# STM32F745 register map
File version: 1.6
CPU: CM7 r0p1, little endian, MPU, FPU, 4 interrupt priority bits
Registers are 32-bit, read-write, reset 0x0 unless marked. A register's access mark holds for its fields unless they carry their own. Offsets are from the block's base; [hi:lo] are bit positions.

## Ethernet_MMC — Ethernet: MAC management counters
Base 0x40028100
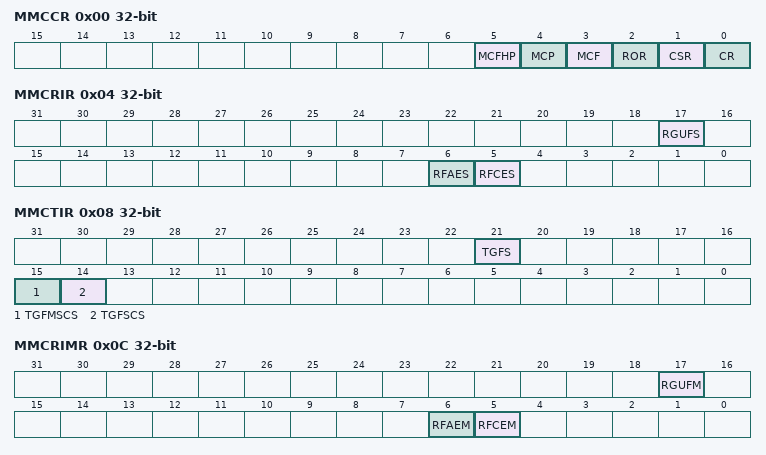
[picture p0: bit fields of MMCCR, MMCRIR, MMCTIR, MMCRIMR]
0x00 MMCCR — Ethernet MMC control register
  [5] MCFHP — MMC counter Full-Half preset
    0=AlmostHalf (When MCP is set, MMC counters are preset to almost-half value 0x7FFF_FFF0); 1=AlmostFull (When MCP is set, MMC counters are preset to almost-full value 0xFFFF_FFF0)
  [4] MCP — MMC counter preset
    1=Preset (MMC counters will be preset to almost full or almost half. Cleared automatically)
  [3] MCF — MMC counter freeze
    0=Unfrozen (All MMC counters update normally); 1=Frozen (All MMC counters frozen to their current value)
  [2] ROR — Reset on read
    0=Disabled (MMC counters do not reset on read); 1=Enabled (MMC counters reset to zero after read)
  [1] CSR — Counter stop rollover
    0=Disabled (Counters roll over to zero after reaching the maximum value); 1=Enabled (Counters do not roll over to zero after reaching the maximum value)
  [0] CR — Counter reset
    1=Reset all counters. Cleared automatically
0x04 MMCRIR — Ethernet MMC receive interrupt register
  [17] RGUFS — Received good Unicast frames status
  [6] RFAES — Received frames alignment error status
  [5] RFCES — Received frames CRC error status
0x08 MMCTIR ro — Ethernet MMC transmit interrupt register
  [21] TGFS — Transmitted good frames status
  [15] TGFMSCS — Transmitted good frames more than single collision status
  [14] TGFSCS — Transmitted good frames single collision status
0x0C MMCRIMR — Ethernet MMC receive interrupt mask register
  [17] RGUFM — Received good Unicast frames mask
    0=Unmasked (Received-good-unicast counter half-full interrupt enabled); 1=Masked (Received-good-unicast counter half-full interrupt disabled)
  [6] RFAEM — Received frames alignment error mask
    0=Unmasked (Received-alignment-error counter half-full interrupt enabled); 1=Masked (Received-alignment-error counter half-full interrupt disabled)
  [5] RFCEM — Received frame CRC error mask
    0=Unmasked (Received-crc-error counter half-full interrupt enabled); 1=Masked (Received-crc-error counter half-full interrupt disabled)
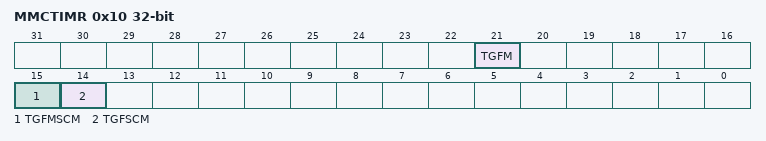
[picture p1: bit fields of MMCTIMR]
0x10 MMCTIMR — Ethernet MMC transmit interrupt mask register
  [21] TGFM — Transmitted good frames mask
    0=Unmasked (Transmitted-good counter half-full interrupt enabled); 1=Masked (Transmitted-good counter half-full interrupt disabled)
  [15] TGFMSCM — Transmitted good frames more than single collision mask
    0=Unmasked (Transmitted-good-multiple-collision half-full interrupt enabled); 1=Masked (Transmitted-good-multiple-collision half-full interrupt disabled)
  [14] TGFSCM — Transmitted good frames single collision mask
    0=Unmasked (Transmitted-good-single-collision half-full interrupt enabled); 1=Masked (Transmitted-good-single-collision half-full interrupt disabled)
0x4C MMCTGFSCCR ro — Ethernet MMC transmitted good frames after a single collision counter
  [31:0] TGFSCC — Transmitted good frames single collision counter
0x50 MMCTGFMSCCR ro — Ethernet MMC transmitted good frames after more than a single collision
  [31:0] TGFMSCC
0x68 MMCTGFCR ro — Ethernet MMC transmitted good frames counter register
  [31:0] TGFC — HTL
0x94 MMCRFCECR ro — Ethernet MMC received frames with CRC error counter register
  [31:0] RFCFC
0x98 MMCRFAECR ro — Ethernet MMC received frames with alignment error counter register
  [31:0] RFAEC
0xC4 MMCRGUFCR ro — MMC received good unicast frames counter register
  [31:0] RGUFC

## Ethernet_PTP — Ethernet: Precision time protocol
Base 0x40028700
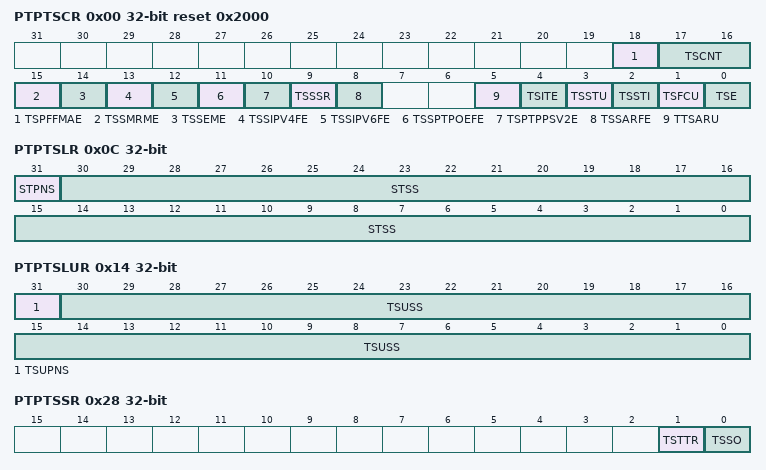
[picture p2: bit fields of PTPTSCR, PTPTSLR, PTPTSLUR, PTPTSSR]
0x00 PTPTSCR reset 0x2000 — Ethernet PTP time stamp control register
  [18] TSPFFMAE, [17:16] TSCNT, [15] TSSMRME, [14] TSSEME, [13] TSSIPV4FE, [12] TSSIPV6FE, [11] TSSPTPOEFE, [10] TSPTPPSV2E, [9] TSSSR, [8] TSSARFE, [5] TTSARU, [4] TSITE, [3] TSSTU, [2] TSSTI, [1] TSFCU, [0] TSE
0x04 PTPSSIR — Ethernet PTP subsecond increment register
  [7:0] STSSI
0x08 PTPTSHR ro — Ethernet PTP time stamp high register
  [31:0] STS
0x0C PTPTSLR ro — Ethernet PTP time stamp low register
  [31] STPNS, [30:0] STSS
0x10 PTPTSHUR — Ethernet PTP time stamp high update register
  [31:0] TSUS
0x14 PTPTSLUR — Ethernet PTP time stamp low update register
  [31] TSUPNS, [30:0] TSUSS
0x18 PTPTSAR — Ethernet PTP time stamp addend register
  [31:0] TSA
0x1C PTPTTHR — Ethernet PTP target time high register
  [31:0] TTSH — 0
0x20 PTPTTLR — Ethernet PTP target time low register
  [31:0] TTSL
0x28 PTPTSSR ro — Ethernet PTP time stamp status register
  [1] TSTTR — TSSO
  [0] TSSO
0x2C PTPPPSCR ro — Ethernet PTP PPS control register
  [3:0] PPSFREQ rw — PPS frequency selection
    0=Hz_1 (1 Hz with a pulse width of 125 ms for binary rollover and of 100 ms for digital rollover); 1=Hz_2 (2 Hz with 50% duty cycle for binary rollover (digital rollover not recommended)); 2=Hz_4 (4 Hz with 50% duty cycle for binary rollover (digital rollover not recommended)); 3=Hz_8 (8 Hz with 50% duty cycle for binary rollover (digital rollover not recommended)); 4=Hz_16 (16 Hz with 50% duty cycle for binary rollover (digital rollover not recommended)); 5=Hz_32 (32 Hz with 50% duty cycle for binary rollover (digital rollover not recommended)); 6=Hz_64 (64 Hz with 50% duty cycle for binary rollover (digital rollover not recommended)); 7=Hz_128 (128 Hz with 50% duty cycle for binary rollover (digital rollover not recommended)); 8=Hz_256 (256 Hz with 50% duty cycle for binary rollover (digital rollover not recommended)); 9=Hz_512 (512 Hz with 50% duty cycle for binary rollover (digital rollover not recommended)); 10=Hz_1024 (1024 Hz with 50% duty cycle for binary rollover (digital rollover not recommended)); 11=Hz_2048 (2048 Hz with 50% duty cycle for binary rollover (digital rollover not recommended)); 12=Hz_4096 (4096 Hz with 50% duty cycle for binary rollover (digital rollover not recommended)); 13=Hz_8192 (8192 Hz with 50% duty cycle for binary rollover (digital rollover not recommended)); 14=Hz_16384 (16384 Hz with 50% duty cycle for binary rollover (digital rollover not recommended)); 15=Hz_32768 (32768 Hz with 50% duty cycle for binary rollover (digital rollover not recommended))
